# AT32F415xx register map
Vendor: Keil; Series: AT32F415; File version: 1.0
CPU: CM4 r0p1, little endian, no MPU, FPU, 4 interrupt priority bits
Registers are 32-bit, read-write, reset 0x0 unless marked. A register's access mark holds for its fields unless they carry their own. Offsets are from the block's base; [hi:lo] are bit positions; {n}, {i} and the like mark numbered series.

## CAN — Controller area network
Base 0x40006400
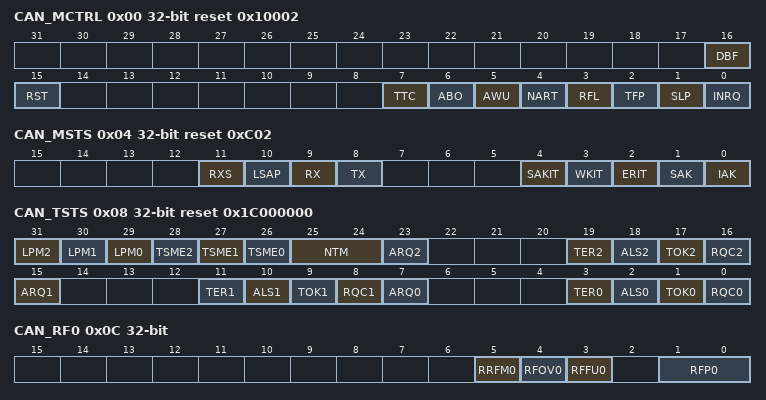
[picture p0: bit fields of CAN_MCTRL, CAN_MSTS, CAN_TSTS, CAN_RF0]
0x00 CAN_MCTRL reset 0x10002
  [16] DBF — Debug freeze
  [15] RST — bxCAN software reset
  [7] TTC — Time triggered communication mode
  [6] ABO — Automatic bus-off management
  [5] AWU — Automatic wakeup mode
  [4] NART — No automatic retransmission
  [3] RFL — Receive FIFO locked mode
  [2] TFP — Transmit FIFO priority
  [1] SLP — Sleep mode request
  [0] INRQ — Initialization request
0x04 CAN_MSTS reset 0xC02
  [11] RXS ro — RX
  [10] LSAP ro — SAMP
  [9] RX ro — RXM
  [8] TX ro — TXM
  [4] SAKIT — SLAKI
  [3] WKIT — WKUI
  [2] ERIT — ERRI
  [1] SAK ro — SLAK
  [0] IAK ro — INAK
0x08 CAN_TSTS reset 0x1C000000
  [31] LPM2 ro — Lowest priority flag for mailbox 2
  [30] LPM1 ro — Lowest priority flag for mailbox 1
  [29] LPM0 ro — Lowest priority flag for mailbox 0
  [28] TSME2 ro — Lowest priority flag for mailbox 2
  [27] TSME1 ro — Lowest priority flag for mailbox 1
  [26] TSME0 ro — Lowest priority flag for mailbox 0
  [25:24] NTM ro — CODE
  [23] ARQ2 — ABRQ2
  [19] TER2 — TERR2
  [18] ALS2 — ALST2
  [17] TOK2 — TXOK2
  [16] RQC2 — RQCP2
  [15] ARQ1 — ABRQ1
  [11] TER1 — TERR1
  [10] ALS1 — ALST1
  [9] TOK1 — TXOK1
  [8] RQC1 — RQCP1
  [7] ARQ0 — ABRQ0
  [3] TER0 — TERR0
  [2] ALS0 — ALST0
  [1] TOK0 — TXOK0
  [0] RQC0 — RQCP0
0x0C CAN_RF0
  [5] RRFM0 — RFOM0
  [4] RFOV0 — FOVR0
  [3] RFFU0 — FULL0
  [1:0] RFP0 ro — FMP0
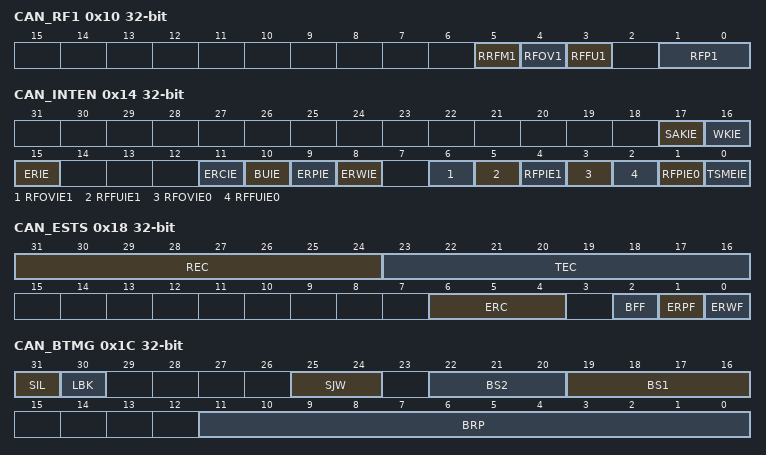
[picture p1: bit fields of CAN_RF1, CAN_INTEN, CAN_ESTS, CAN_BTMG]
0x10 CAN_RF1
  [5] RRFM1 — RFOM1
  [4] RFOV1 — FOVR1
  [3] RFFU1 — FULL1
  [1:0] RFP1 ro — FMP1
0x14 CAN_INTEN
  [17] SAKIE — SLKIE
  [16] WKIE — WKUIE
  [15] ERIE — ERRIE
  [11] ERCIE — LECIE
  [10] BUIE — BOFIE
  [9] ERPIE — EPVIE
  [8] ERWIE — EWGIE
  [6] RFOVIE1 — FOVIE1
  [5] RFFUIE1 — FFIE1
  [4] RFPIE1 — FMPIE1
  [3] RFOVIE0 — FOVIE0
  [2] RFFUIE0 — FFIE0
  [1] RFPIE0 — FMPIE0
  [0] TSMEIE — TMEIE
0x18 CAN_ESTS
  [31:24] REC ro
  [23:16] TEC ro
  [6:4] ERC — LEC
  [2] BFF ro — BOFF
  [1] ERPF ro — EPVF
  [0] ERWF ro — EWGF
0x1C CAN_BTMG
  [31] SIL — SILM
  [30] LBK — LBKM
  [25:24] SJW
  [22:20] BS2 — TS2
  [19:16] BS1 — TS1
  [11:0] BRP
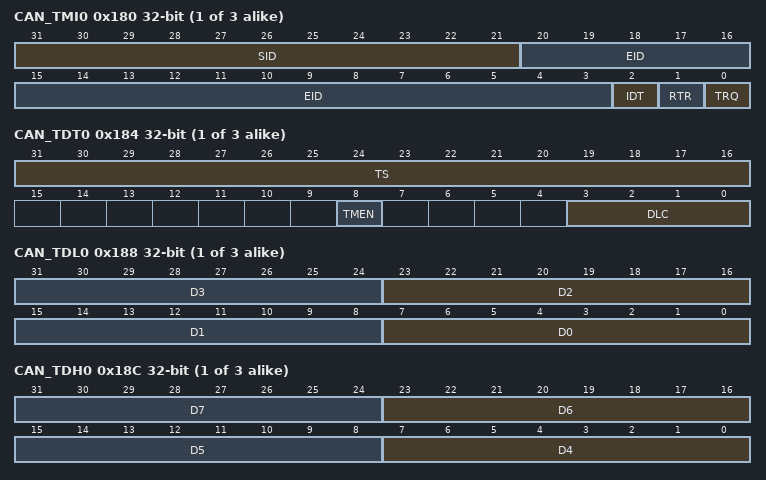
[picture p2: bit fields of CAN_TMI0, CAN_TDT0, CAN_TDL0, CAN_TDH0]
{0x180+0x10*i} CAN_TMI{i} (i=0..2)
  [31:21] SID — STID
  [20:3] EID — EXID
  [2] IDT — IDE
  [1] RTR
  [0] TRQ — TXRQ
{0x184+0x10*i} CAN_TDT{i} (i=0..2)
  [31:16] TS, [8] TMEN, [3:0] DLC
{0x188+0x10*i} CAN_TDL{i} (i=0..2)
  [8n+7:8n] D{n} (n=0..3) — DATA{n}
{0x18C+0x10*i} CAN_TDH{i} (i=0..2)
  [8n-25:8n-32] D{n} (n=4..7) — DATA{n}
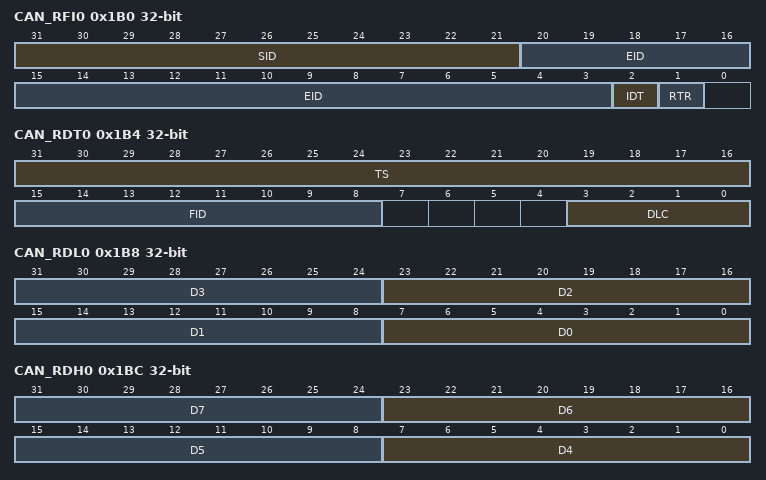
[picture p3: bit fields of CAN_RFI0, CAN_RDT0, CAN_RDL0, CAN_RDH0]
0x1B0 CAN_RFI0 ro
  [31:21] SID, [20:3] EID, [2] IDT, [1] RTR
0x1B4 CAN_RDT0 ro
  [31:16] TS, [15:8] FID, [3:0] DLC
0x1B8 CAN_RDL0 ro
  [8n+7:8n] D{n} (n=0..3) — DATA{n}
0x1BC CAN_RDH0 ro
  [8n-25:8n-32] D{n} (n=4..7) — DATA{n}
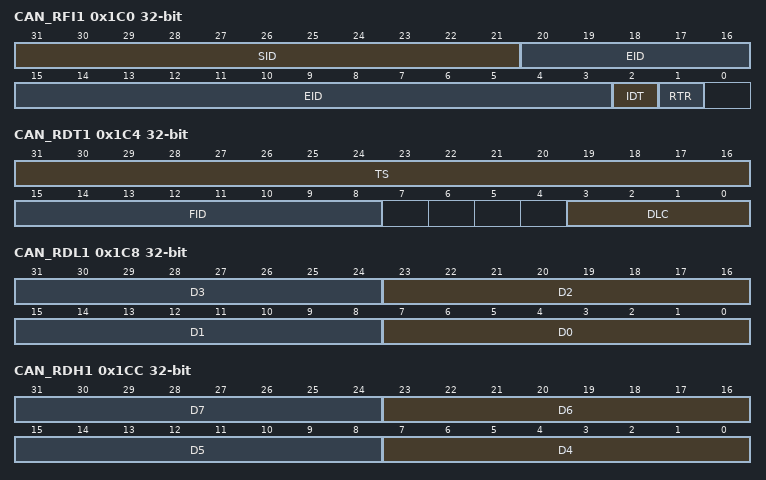
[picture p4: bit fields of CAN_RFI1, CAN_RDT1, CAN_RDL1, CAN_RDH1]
0x1C0 CAN_RFI1 ro
  [31:21] SID, [20:3] EID, [2] IDT, [1] RTR
0x1C4 CAN_RDT1 ro
  [31:16] TS, [15:8] FID, [3:0] DLC
0x1C8 CAN_RDL1 ro
  [8n+7:8n] D{n} (n=0..3) — DATA{n}
0x1CC CAN_RDH1 ro
  [8n-25:8n-32] D{n} (n=4..7) — DATA{n}
0x200 CAN_FM
  [0] FINT
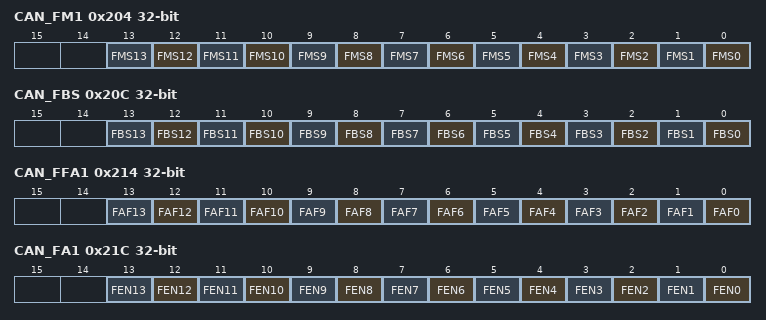
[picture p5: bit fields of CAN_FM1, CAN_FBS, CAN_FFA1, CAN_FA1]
0x204 CAN_FM1
  [n] FMS{n} (n=0..13) — Filter mode
0x20C CAN_FBS
  [n] FBS{n} (n=0..13) — Filter scale configuration
0x214 CAN_FFA1
  [n] FAF{n} (n=0..13) — Filter FIFO assignment for filter {n}
0x21C CAN_FA1
  [n] FEN{n} (n=0..13) — Filter active
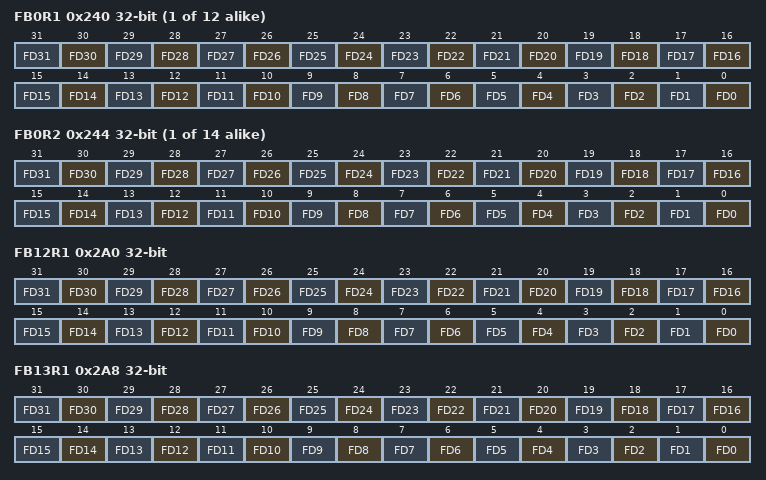
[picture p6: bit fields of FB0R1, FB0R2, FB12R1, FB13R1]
{0x240+8i} FB{i}R1 (i=0..11) — Filter bank {i} register 1
  [n] FD{n} (n=0..31) — Filter bits
{0x244+8i} FB{i}R2 (i=0..13) — Filter bank {i} register 2
  [n] FD{n} (n=0..31) — Filter bits
0x2A0 FB12R1 — Filter bank 4 register 1
  [n] FD{n} (n=0..31) — Filter bits
0x2A8 FB13R1 — Filter bank 13 register 1
  [n] FD{n} (n=0..31) — Filter bits

## COMP — Compare
Base 0x40002400
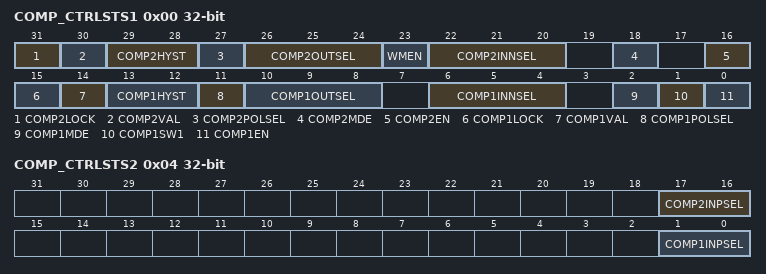
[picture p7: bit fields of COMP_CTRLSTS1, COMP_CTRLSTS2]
0x00 COMP_CTRLSTS1 — Comp1 control/status register
  [31] COMP2LOCK — COMP_CSR1[31:16] and COMP_CSR2 register lock bit
  [30] COMP2VAL ro — Comparator 2 output status bit
  [29:28] COMP2HYST — Comparator 2 hysteresis bit
  [27] COMP2POLSEL — Comparator 2 polarity selection bit
  [26:24] COMP2OUTSEL — Comparator 2 output selection bit
  [23] WMEN — Window mode enable bit
  [22:20] COMP2INNSEL — Comparator 2 inverting input selection
  [18] COMP2MDE — Comparator 2 mode
  [16] COMP2EN — Comparator 2 enable bit
  [15] COMP1LOCK — COMP_CSR1[15:0] and COMP_CSR2[15:0] register lock bit
  [14] COMP1VAL ro — Comparator 1 output status bit
  [13:12] COMP1HYST — Comparator 1 hysteresis bit
  [11] COMP1POLSEL — Comparator 1 polarity selection bit
  [10:8] COMP1OUTSEL — Comparator 1 output selection bit
  [6:4] COMP1INNSEL — Comparator 1 inverting input selection
  [2] COMP1MDE — Comparator 1 mode
  [1] COMP1SW1 — Comparator 1 non inverting input DAC switch
  [0] COMP1EN — Comparator 1 enable bit
0x04 COMP_CTRLSTS2 — Comp2 control/status register
  [17:16] COMP2INPSEL — Comparator 2 non-inverting input selection
  [1:0] COMP1INPSEL — Comparator 1 non-inverting input selection
0x08 G_FILTER_EN
  [0] GFE — Glitch filter enable
0x0C HIGH_PULSE
  [5:0] H_PULSE_CNT — High pulse Count
0x10 LOW_PULSE
  [5:0] L_PULSE_CNT — Low pulse Count
